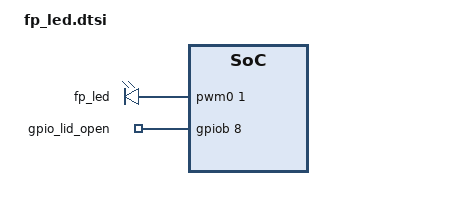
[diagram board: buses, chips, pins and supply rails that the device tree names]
/* Copyright 2026 The ChromiumOS Authors.
 * Use of this source code is governed by a BSD-style license that can be
 * found in the LICENSE file.
 */

/{
	pwmleds {
		compatible = "pwm-leds";

		fp_led: fp_led {
			pwms = <&pwm0 1 PWM_MSEC(20) PWM_POLARITY_NORMAL>;
		};
	};

	gpio-keys {
		compatible = "gpio-keys";

		gpio_lid_open: gpio_lid_open {
			gpios = <&gpiob 8 (GPIO_PULL_UP | GPIO_ACTIVE_HIGH)>;
		};
	};

	aliases {
		pwm-fp-led = &fp_led;
		gpio-lid-open = &gpio_lid_open;
	};
};
